# STM32F722ICK6 register map
File version: 1.0
Registers are 32-bit, access not given, reset 0x0 unless marked. A register's access mark holds for its fields unless they carry their own. Offsets are from the block's base; [hi:lo] are bit positions; {n}, {i} and the like mark numbered series; 'fields as' and 'values as' point back to an identical list.

## USBPHYC
Base 0x40017C00
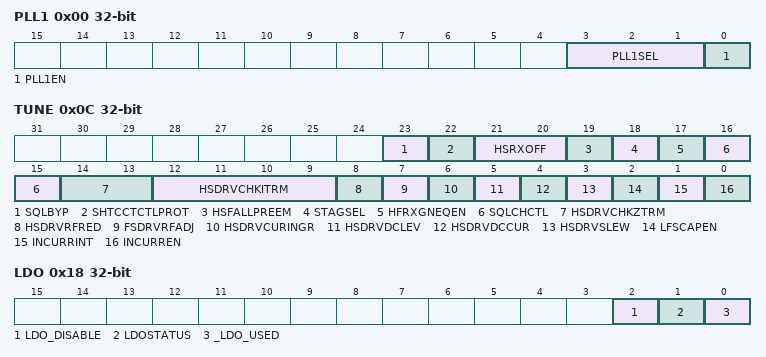
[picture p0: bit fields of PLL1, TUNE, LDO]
0x00 PLL1
  [3:1] PLL1SEL, [0] PLL1EN
0x0C TUNE
  [23] SQLBYP, [22] SHTCCTCTLPROT, [21:20] HSRXOFF, [19] HSFALLPREEM, [18] STAGSEL, [17] HFRXGNEQEN, [16:15] SQLCHCTL, [14:13] HSDRVCHKZTRM, [12:9] HSDRVCHKITRM, [8] HSDRVRFRED, [7] FSDRVRFADJ, [6] HSDRVCURINGR, [5] HSDRVDCLEV, [4] HSDRVDCCUR, [3] HSDRVSLEW, [2] LFSCAPEN, [1] INCURRINT, [0] INCURREN
0x18 LDO
  [2] LDO_DISABLE, [1] LDOSTATUS, [0] _LDO_USED

## GPIOA
Base 0x40020000
Same registers: GPIOB 0x40020400
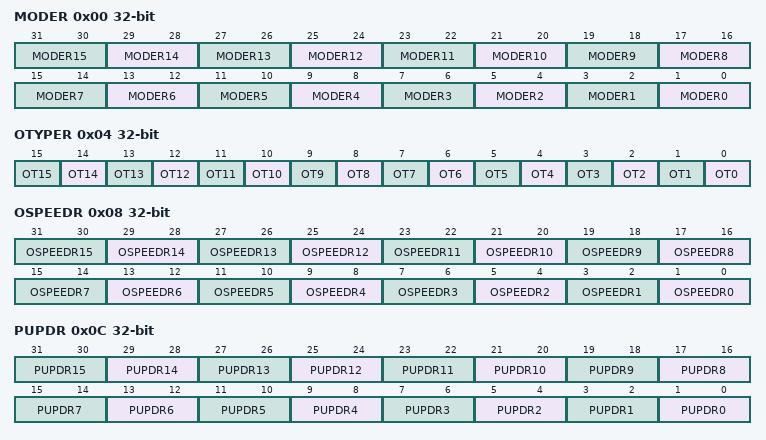
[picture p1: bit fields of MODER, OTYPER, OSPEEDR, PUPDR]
0x00 MODER
  [2n+1:2n] MODER{n} (n=0..15)
0x04 OTYPER
  [n] OT{n} (n=0..15)
0x08 OSPEEDR
  [2n+1:2n] OSPEEDR{n} (n=0..15)
0x0C PUPDR
  [2n+1:2n] PUPDR{n} (n=0..15)
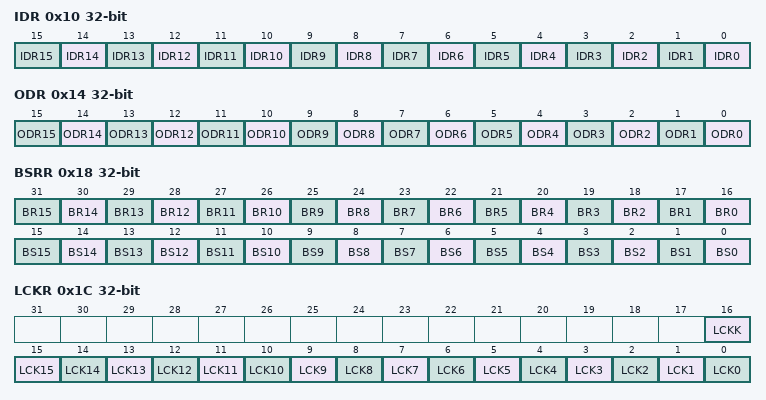
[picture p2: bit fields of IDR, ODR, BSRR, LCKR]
0x10 IDR
  [n] IDR{n} (n=0..15)
0x14 ODR
  [n] ODR{n} (n=0..15)
0x18 BSRR
  [n+16] BR{n} (n=0..15), [n] BS{n} (n=0..15)
0x1C LCKR
  [16] LCKK, [n] LCK{n} (n=0..15)
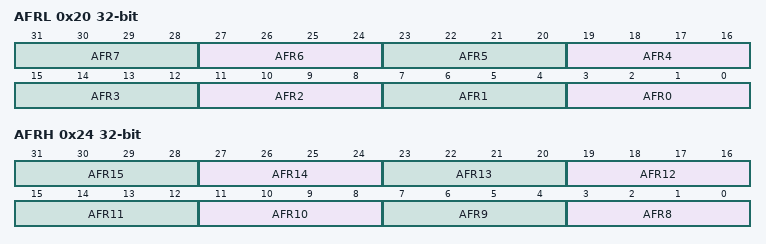
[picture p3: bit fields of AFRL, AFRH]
0x20 AFRL
  [4n+3:4n] AFR{n} (n=0..7)
0x24 AFRH
  [4n-29:4n-32] AFR{n} (n=8..15)

## GPIOC
Base 0x40020800
Registers as GPIOA, without PUPDR.

## GPIOD
Base 0x40020C00
Registers as GPIOA, without PUPDR.

## GPIOE
Base 0x40021000
Registers as GPIOA, without PUPDR.

## GPIOF
Base 0x40021400
Registers as GPIOA, without PUPDR.

## GPIOG
Base 0x40021800
Registers as GPIOA, without PUPDR.

## GPIOH
Base 0x40021C00
Registers as GPIOA, without PUPDR.

## GPIOI
Base 0x40022000
Registers as GPIOA, without PUPDR.

## CRC
Base 0x40023000
0x00 DR
0x04 IDR
  [7:0] IDR
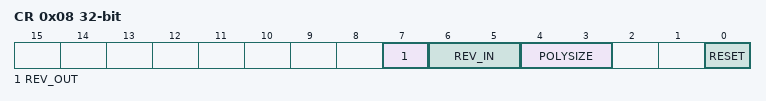
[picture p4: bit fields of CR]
0x08 CR
  [7] REV_OUT, [6:5] REV_IN, [4:3] POLYSIZE, [0] RESET
0x10 INIT
  [31:0] CRC_INIT
0x14 POL
  [31:0] Polynomialcoefficients

## FLASH
Base 0x40023C00
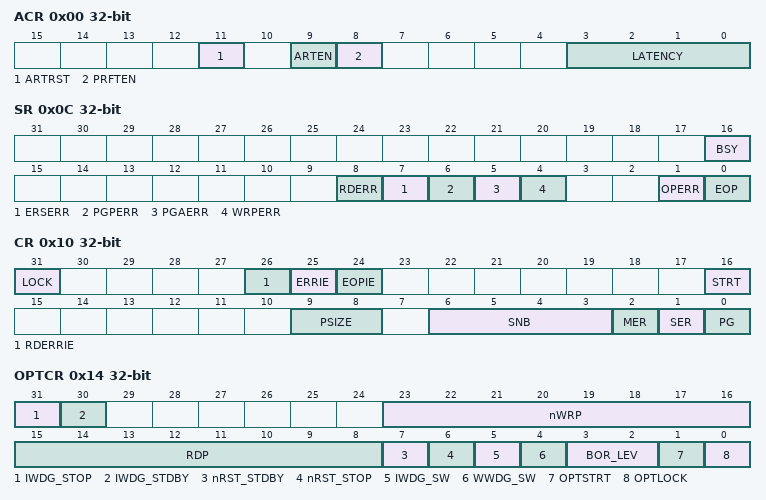
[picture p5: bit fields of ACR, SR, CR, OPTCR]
0x00 ACR
  [11] ARTRST, [9] ARTEN, [8] PRFTEN, [3:0] LATENCY
0x04 KEYR
  [31:0] KEY
0x08 OPTKEYR
0x0C SR
  [16] BSY, [8] RDERR, [7] ERSERR, [6] PGPERR, [5] PGAERR, [4] WRPERR, [1] OPERR, [0] EOP
0x10 CR
  [31] LOCK, [26] RDERRIE, [25] ERRIE, [24] EOPIE, [16] STRT, [9:8] PSIZE, [6:3] SNB, [2] MER, [1] SER, [0] PG
0x14 OPTCR
  [31] IWDG_STOP, [30] IWDG_STDBY, [23:16] nWRP, [15:8] RDP, [7] nRST_STDBY, [6] nRST_STOP, [5] IWDG_SW, [4] WWDG_SW, [3:2] BOR_LEV, [1] OPTSTRT, [0] OPTLOCK
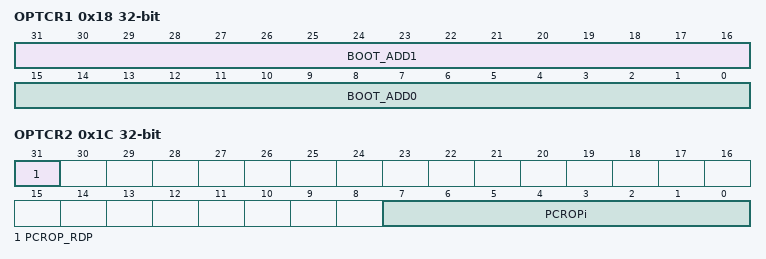
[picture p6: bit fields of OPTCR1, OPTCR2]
0x18 OPTCR1
  [31:16] BOOT_ADD1, [15:0] BOOT_ADD0
0x1C OPTCR2
  [31] PCROP_RDP, [7:0] PCROPi

## DMA1
Base 0x40026000
Same registers: DMA2 0x40026400
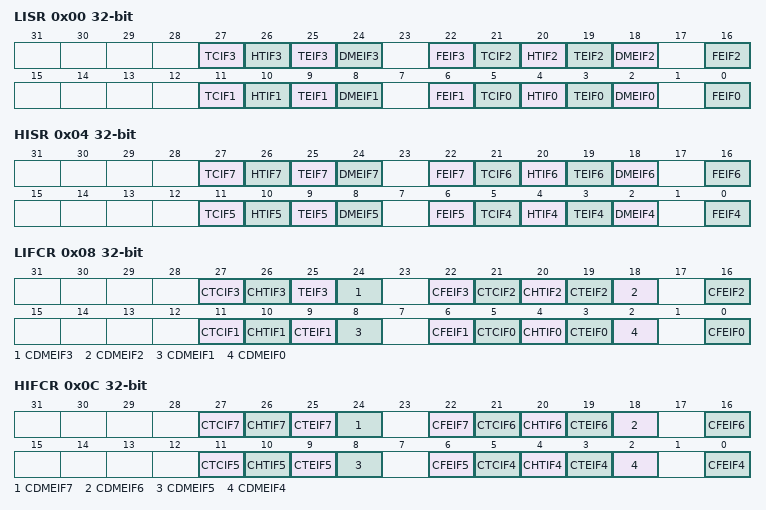
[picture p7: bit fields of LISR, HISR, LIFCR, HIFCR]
0x00 LISR
  [27] TCIF3, [26] HTIF3, [25] TEIF3, [24] DMEIF3, [22] FEIF3, [21] TCIF2, [20] HTIF2, [19] TEIF2, [18] DMEIF2, [16] FEIF2, [11] TCIF1, [10] HTIF1, [9] TEIF1, [8] DMEIF1, [6] FEIF1, [5] TCIF0, [4] HTIF0, [3] TEIF0, [2] DMEIF0, [0] FEIF0
0x04 HISR
  [27] TCIF7, [26] HTIF7, [25] TEIF7, [24] DMEIF7, [22] FEIF7, [21] TCIF6, [20] HTIF6, [19] TEIF6, [18] DMEIF6, [16] FEIF6, [11] TCIF5, [10] HTIF5, [9] TEIF5, [8] DMEIF5, [6] FEIF5, [5] TCIF4, [4] HTIF4, [3] TEIF4, [2] DMEIF4, [0] FEIF4
0x08 LIFCR
  [27] CTCIF3, [26] CHTIF3, [25] TEIF3, [24] CDMEIF3, [22] CFEIF3, [21] CTCIF2, [20] CHTIF2, [19] CTEIF2, [18] CDMEIF2, [16] CFEIF2, [11] CTCIF1, [10] CHTIF1, [9] CTEIF1, [8] CDMEIF1, [6] CFEIF1, [5] CTCIF0, [4] CHTIF0, [3] CTEIF0, [2] CDMEIF0, [0] CFEIF0
0x0C HIFCR
  [27] CTCIF7, [26] CHTIF7, [25] CTEIF7, [24] CDMEIF7, [22] CFEIF7, [21] CTCIF6, [20] CHTIF6, [19] CTEIF6, [18] CDMEIF6, [16] CFEIF6, [11] CTCIF5, [10] CHTIF5, [9] CTEIF5, [8] CDMEIF5, [6] CFEIF5, [5] CTCIF4, [4] CHTIF4, [3] CTEIF4, [2] CDMEIF4, [0] CFEIF4
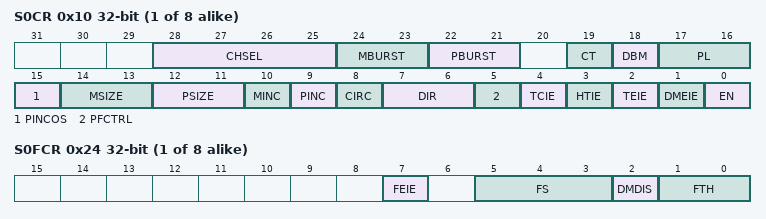
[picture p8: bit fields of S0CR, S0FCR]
{0x10+0x18*i} S{i}CR (i=0..7)
  [28:25] CHSEL, [24:23] MBURST, [22:21] PBURST, [19] CT, [18] DBM, [17:16] PL, [15] PINCOS, [14:13] MSIZE, [12:11] PSIZE, [10] MINC, [9] PINC, [8] CIRC, [7:6] DIR, [5] PFCTRL, [4] TCIE, [3] HTIE, [2] TEIE, [1] DMEIE, [0] EN
{0x14+0x18*i} S{i}NDTR (i=0..7)
  [15:0] NDT
{0x18+0x18*i} S{i}PAR (i=0..7)
  [31:0] PA
{0x1C+0x18*i} S{i}M0AR (i=0..7)
  [31:0] M0A
{0x20+0x18*i} S{i}M1AR (i=0..7)
  [31:0] M1A
{0x24+0x18*i} S{i}FCR (i=0..7)
  [7] FEIE, [5:3] FS, [2] DMDIS, [1:0] FTH

## AES
Base 0x50060000
0x00 CR
  [18] KEYSIZE, [14:13] GCMPH, [12] DMAOUTEN, [11] DMAINEN, [10] ERRIE, [9] CCFIE, [8] ERRC, [7] CCFC, [16:5] CHMOD, [4:3] MODE, [2:1] DATATYPE, [0] EN
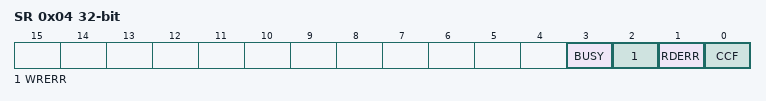
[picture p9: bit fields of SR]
0x04 SR
  [3] BUSY, [2] WRERR, [1] RDERR, [0] CCF
0x08 DINR
  [31:0] DIN
0x0C DOUTR
  [31:0] DOUT
{0x10+4i} KEYR{i} (i=0..3)
  [31:0] KEY
{0x20+4i} IVR{i} (i=0..3)
  [31:0] IVI
{0x20+4i} KEYR{i} (i=4..7)
  [31:0] KEY
{0x40+4i} SUSP{i}R (i=0..7)
  [31:0] SUSP{i}

## RNG
Base 0x50060800
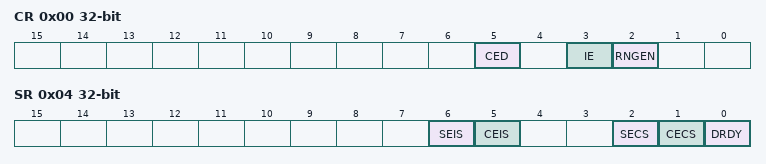
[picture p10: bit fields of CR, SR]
0x00 CR
  [5] CED, [3] IE, [2] RNGEN
0x04 SR
  [6] SEIS, [5] CEIS, [2] SECS, [1] CECS, [0] DRDY
0x08 DR
  [31:0] RNDATA

## FMC
Base 0xA0000000
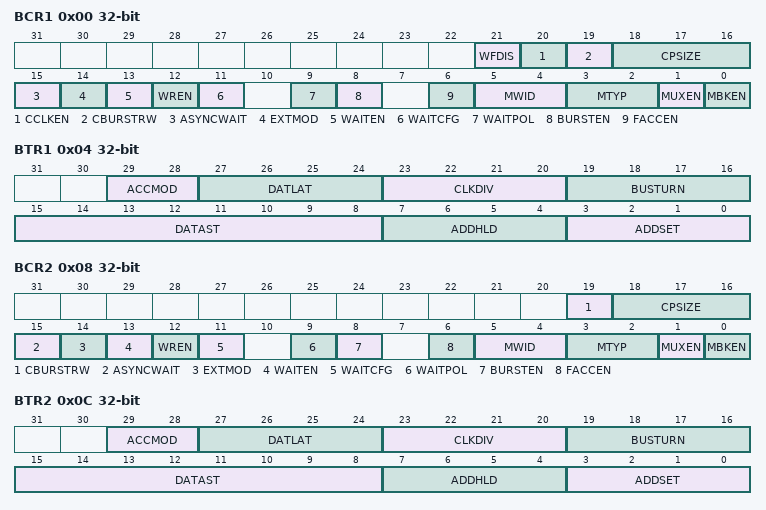
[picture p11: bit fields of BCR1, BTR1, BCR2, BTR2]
0x00 BCR1
  [21] WFDIS, [20] CCLKEN, [19] CBURSTRW, [18:16] CPSIZE, [15] ASYNCWAIT, [14] EXTMOD, [13] WAITEN, [12] WREN, [11] WAITCFG, [9] WAITPOL, [8] BURSTEN, [6] FACCEN, [5:4] MWID, [3:2] MTYP, [1] MUXEN, [0] MBKEN
0x04 BTR1
  [29:28] ACCMOD, [27:24] DATLAT, [23:20] CLKDIV, [19:16] BUSTURN, [15:8] DATAST, [7:4] ADDHLD, [3:0] ADDSET
0x08 BCR2
  [19] CBURSTRW, [18:16] CPSIZE, [15] ASYNCWAIT, [14] EXTMOD, [13] WAITEN, [12] WREN, [11] WAITCFG, [9] WAITPOL, [8] BURSTEN, [6] FACCEN, [5:4] MWID, [3:2] MTYP, [1] MUXEN, [0] MBKEN
0x0C BTR2
  fields as BTR1
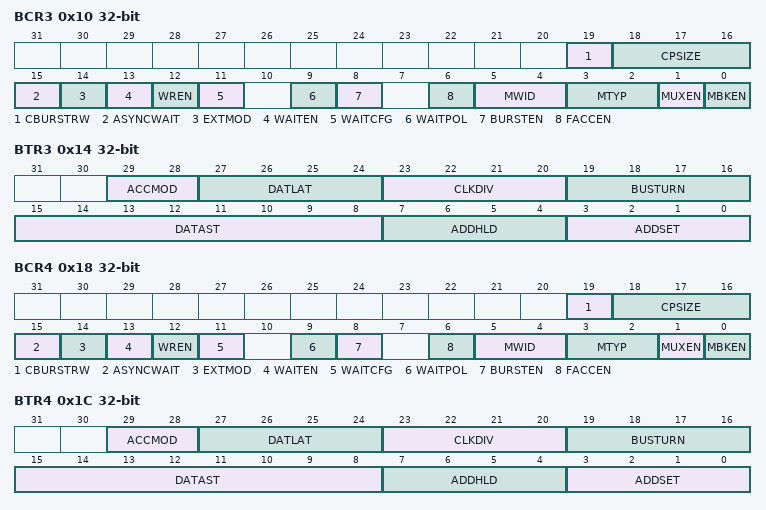
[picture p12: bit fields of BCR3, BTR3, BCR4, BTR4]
0x10 BCR3
  fields as BCR2
0x14 BTR3
  fields as BTR1
0x18 BCR4
  fields as BCR2
0x1C BTR4
  fields as BTR1
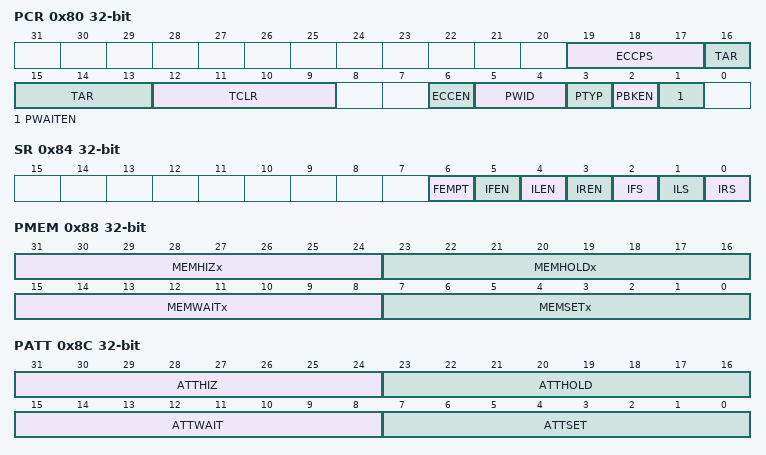
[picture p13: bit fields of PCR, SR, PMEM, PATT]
0x80 PCR
  [19:17] ECCPS, [16:13] TAR, [12:9] TCLR, [6] ECCEN, [5:4] PWID, [3] PTYP, [2] PBKEN, [1] PWAITEN
0x84 SR
  [6] FEMPT, [5] IFEN, [4] ILEN, [3] IREN, [2] IFS, [1] ILS, [0] IRS
0x88 PMEM
  [31:24] MEMHIZx, [23:16] MEMHOLDx, [15:8] MEMWAITx, [7:0] MEMSETx
0x8C PATT
  [31:24] ATTHIZ, [23:16] ATTHOLD, [15:8] ATTWAIT, [7:0] ATTSET
0x94 ECCR
  [31:0] ECCx
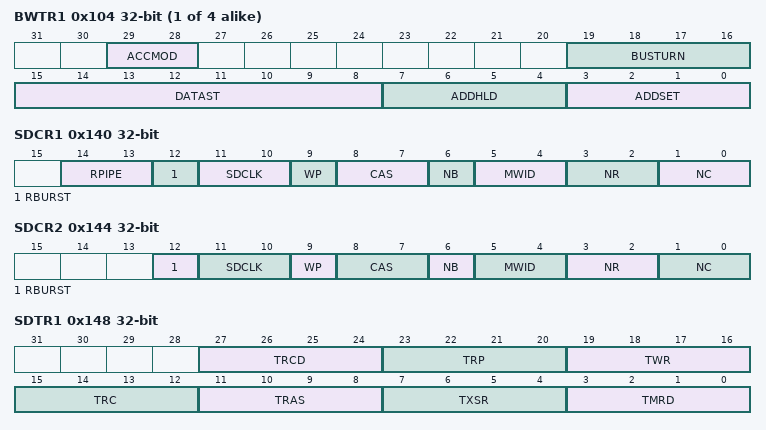
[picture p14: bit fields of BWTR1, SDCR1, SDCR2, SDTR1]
{0xFC+8i} BWTR{i} (i=1..4)
  [29:28] ACCMOD, [19:16] BUSTURN, [15:8] DATAST, [7:4] ADDHLD, [3:0] ADDSET
0x140 SDCR1
  [14:13] RPIPE, [12] RBURST, [11:10] SDCLK, [9] WP, [8:7] CAS, [6] NB, [5:4] MWID, [3:2] NR, [1:0] NC
0x144 SDCR2
  [12] RBURST, [11:10] SDCLK, [9] WP, [8:7] CAS, [6] NB, [5:4] MWID, [3:2] NR, [1:0] NC
0x148 SDTR1
  [27:24] TRCD, [23:20] TRP, [19:16] TWR, [15:12] TRC, [11:8] TRAS, [7:4] TXSR, [3:0] TMRD
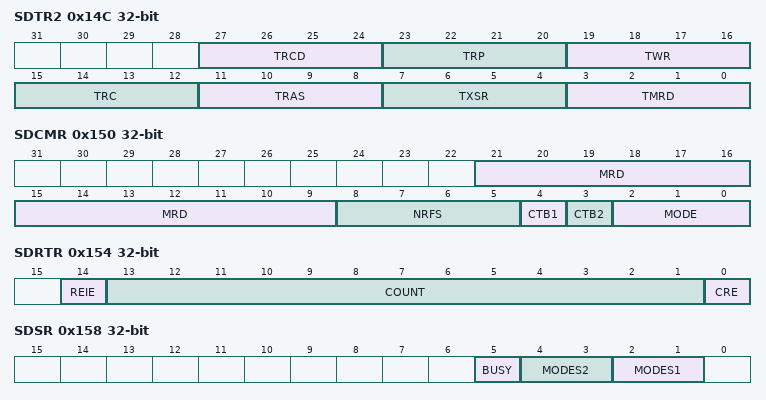
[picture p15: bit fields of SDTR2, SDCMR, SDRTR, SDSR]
0x14C SDTR2
  fields as SDTR1
0x150 SDCMR
  [21:9] MRD, [8:5] NRFS, [4] CTB1, [3] CTB2, [2:0] MODE
0x154 SDRTR
  [14] REIE, [13:1] COUNT, [0] CRE
0x158 SDSR
  [5] BUSY, [4:3] MODES2, [2:1] MODES1

## QSPICR
Base 0xA0001000
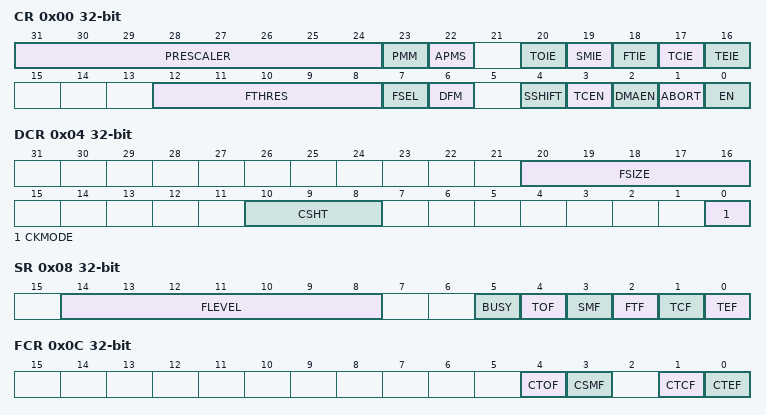
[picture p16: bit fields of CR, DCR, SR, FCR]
0x00 CR
  [31:24] PRESCALER, [23] PMM, [22] APMS, [20] TOIE, [19] SMIE, [18] FTIE, [17] TCIE, [16] TEIE, [12:8] FTHRES, [7] FSEL, [6] DFM, [4] SSHIFT, [3] TCEN, [2] DMAEN, [1] ABORT, [0] EN
0x04 DCR
  [20:16] FSIZE, [10:8] CSHT, [0] CKMODE
0x08 SR
  [14:8] FLEVEL, [5] BUSY, [4] TOF, [3] SMF, [2] FTF, [1] TCF, [0] TEF
0x0C FCR
  [4] CTOF, [3] CSMF, [1] CTCF, [0] CTEF
0x10 DLR
  [31:0] DL
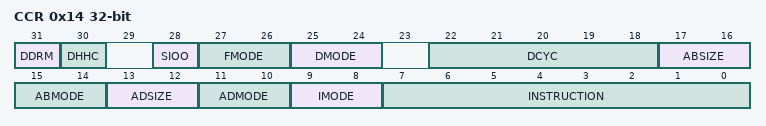
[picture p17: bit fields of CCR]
0x14 CCR
  [31] DDRM, [30] DHHC, [28] SIOO, [27:26] FMODE, [25:24] DMODE, [22:18] DCYC, [17:16] ABSIZE, [15:14] ABMODE, [13:12] ADSIZE, [11:10] ADMODE, [9:8] IMODE, [7:0] INSTRUCTION
0x18 AR
  [31:0] ADDRESS
0x1C ABR
  [31:0] ALTERNATE
0x20 DR
  [31:0] DATA
0x24 PSMKR
  [31:0] MASK
0x28 PSMAR
  [31:0] MATCH
0x2C PIR
  [15:0] INTERVAL
0x30 LPTR
  [15:0] TIMEOUT
